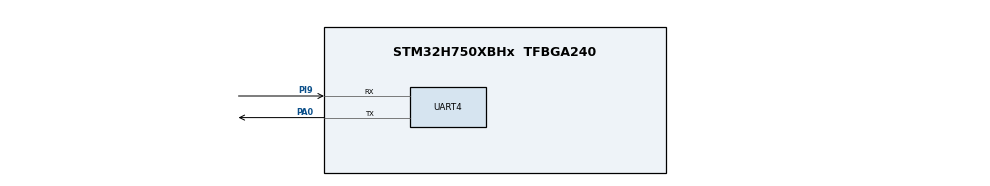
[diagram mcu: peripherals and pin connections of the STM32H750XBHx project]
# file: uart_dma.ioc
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Mcu.Family=STM32H7
Mcu.Name=STM32H750XBHx
Mcu.Package=TFBGA240
NVIC.PriorityGroup=NVIC_PRIORITYGROUP_4
NVIC.UART4_IRQn=true\:0\:0\:false\:false\:true\:true\:true\:true
PA0.Mode=Asynchronous
PA0.Signal=UART4_TX
PH0-OSC_IN\ (PH0).Mode=HSE-External-Oscillator
PH0-OSC_IN\ (PH0).PinAttribute=Free
PH0-OSC_IN\ (PH0).Signal=RCC_OSC_IN
PH1-OSC_OUT\ (PH1).Mode=HSE-External-Oscillator
PH1-OSC_OUT\ (PH1).PinAttribute=Free
PH1-OSC_OUT\ (PH1).Signal=RCC_OSC_OUT
PI9.Mode=Asynchronous
PI9.PinAttribute=Free
PI9.Signal=UART4_RX
ProjectManager.HeapSize=0x200
ProjectManager.StackSize=0x400
ProjectManager.TargetToolchain=STM32CubeIDE
RCC.ADCFreq_Value=480000000
RCC.APB1Freq_Value=120000000
RCC.APB2Freq_Value=120000000
RCC.APB3Freq_Value=120000000
RCC.APB4Freq_Value=120000000
RCC.CortexFreq_Value=480000000
RCC.D1PPRE=RCC_APB3_DIV2
RCC.D2PPRE1=RCC_APB1_DIV2
RCC.D2PPRE2=RCC_APB2_DIV2
RCC.D3PPRE=RCC_APB4_DIV2
RCC.DIVM1=5
RCC.DIVM2=5
RCC.DIVM3=5
RCC.DIVN1=192
RCC.DIVN2=192
RCC.DIVN3=192
RCC.DIVQ2=10
RCC.EnableHSEDSI-ClockTree=true
RCC.HCLKFreq_Value=240000000
RCC.HPRE=RCC_HCLK_DIV2
RCC.PLLSourceVirtual=RCC_PLLSOURCE_HSE
RCC.SYSCLKFreq_VALUE=480000000
RCC.SYSCLKSource=RCC_SYSCLKSOURCE_PLLCLK
RCC.USART234578CLockSelection=RCC_USART234578CLKSOURCE_PLL2
RCC.USBFreq_Value=480000000
board=custom

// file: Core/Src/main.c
/* USER CODE BEGIN Header */
/**
  ******************************************************************************
  * @file           : main.c
  * @brief          : Main program body
  ******************************************************************************
  * @attention
  *
  * Copyright (c) 2023 STMicroelectronics.
  * All rights reserved.
  *
  * This software is licensed under terms that can be found in the LICENSE file
  * in the root directory of this software component.
  * If no LICENSE file comes with this software, it is provided AS-IS.
  *
  ******************************************************************************
  */
/* USER CODE END Header */
#include "main.h"
#include "dma.h"
#include "usart.h"
#include "gpio.h"

/* USER CODE BEGIN Includes */
#include <string.h>
/* USER CODE END Includes */

/* USER CODE BEGIN PV */
extern volatile uint8_t uart4_rx_data;
extern volatile uint8_t uart4_rx_buff[100];
extern volatile uint8_t uart4_rx_cplt_flag;
extern volatile uint8_t uart4_tx_cplt_flag;
extern volatile uint8_t uart4_tx_buff[100];

/* USER CODE END PV */

void SystemClock_Config(void);
/* USER CODE BEGIN PFP */
#ifdef __GNUC__
//With GCC, small printf (option LD Linker->Libraries->Small printf set to 'Yes') calls __io_putchar()
#define PUTCHAR_PROTOTYPE int __io_putchar(int ch)
#else
#define PUTCHAR_PROTOTYPE int fputc(int ch, FILE *f)
#endif /* __GNUC__ */

/* USER CODE END PFP */

int main(void)
{

  /* MCU Configuration--------------------------------------------------------*/

  /* Reset of all peripherals, Initializes the Flash interface and the Systick. */
  HAL_Init();

  /* Configure the system clock */
  SystemClock_Config();

  /* Initialize all configured peripherals */
  MX_GPIO_Init();
  MX_DMA_Init();
  MX_UART4_Init();
  /* USER CODE BEGIN 2 */
  HAL_UART_Receive_IT(&huart4, &uart4_rx_data, 1);
  printf("start main\r\n");
  /* USER CODE END 2 */

  /* Infinite loop */
  /* USER CODE BEGIN WHILE */
  uint8_t print_buf[100] = {0,};
  for (int i = 0; i < 100; i++)
  {
    if(i % 10 )
      uart4_tx_buff[i] = 'z';
    else
      uart4_tx_buff[i] = '0';
  }
  uart4_tx_buff[99] = '\n';

  uint32_t pretime = HAL_GetTick();
  //HAL_UART_Transmit_DMA(&huart4, uart4_tx_buff, sizeof (uart4_tx_buff));
  uint32_t curtime = HAL_GetTick();

  while (1)
  {
    HAL_Delay(1000);
    if(uart4_rx_cplt_flag){
      pretime = HAL_GetTick();
      //printf("%s\r\n", uart4_rx_buff);
      //printf("time : %d", curtime - pretime);
      HAL_UART_Transmit_DMA(&huart4, uart4_tx_buff, sizeof (uart4_tx_buff));
      curtime = HAL_GetTick();
      //

      uart4_rx_cplt_flag = 0;
    }

    if(uart4_tx_cplt_flag){
      HAL_UART_Transmit(&huart4, uart4_tx_buff,sizeof(uart4_tx_buff),0xFFFF);
      sprintf(print_buf, "time : %d\r\n", curtime - pretime);
      HAL_UART_Transmit(&huart4, print_buf, strlen(print_buf), 0xFFFF);
      uart4_tx_cplt_flag = 0;
    }
    /* USER CODE END WHILE */

  }
}

void SystemClock_Config(void)
{
  RCC_OscInitTypeDef RCC_OscInitStruct = {0};
  RCC_ClkInitTypeDef RCC_ClkInitStruct = {0};

  /** Supply configuration update enable
  */
  HAL_PWREx_ConfigSupply(PWR_LDO_SUPPLY);

  /** Configure the main internal regulator output voltage
  */
  __HAL_PWR_VOLTAGESCALING_CONFIG(PWR_REGULATOR_VOLTAGE_SCALE0);

  while(!__HAL_PWR_GET_FLAG(PWR_FLAG_VOSRDY)) {}

  /** Macro to configure the PLL clock source
  */
  __HAL_RCC_PLL_PLLSOURCE_CONFIG(RCC_PLLSOURCE_HSE);

  /** Initializes the RCC Oscillators according to the specified parameters
  * in the RCC_OscInitTypeDef structure.
  */
  RCC_OscInitStruct.OscillatorType = RCC_OSCILLATORTYPE_HSE;
  RCC_OscInitStruct.HSEState = RCC_HSE_ON;
  RCC_OscInitStruct.PLL.PLLState = RCC_PLL_ON;
  RCC_OscInitStruct.PLL.PLLSource = RCC_PLLSOURCE_HSE;
  RCC_OscInitStruct.PLL.PLLM = 5;
  RCC_OscInitStruct.PLL.PLLN = 192;
  RCC_OscInitStruct.PLL.PLLP = 2;
  RCC_OscInitStruct.PLL.PLLQ = 2;
  RCC_OscInitStruct.PLL.PLLR = 2;
  RCC_OscInitStruct.PLL.PLLRGE = RCC_PLL1VCIRANGE_2;
  RCC_OscInitStruct.PLL.PLLVCOSEL = RCC_PLL1VCOWIDE;
  RCC_OscInitStruct.PLL.PLLFRACN = 0;
  if (HAL_RCC_OscConfig(&RCC_OscInitStruct) != HAL_OK)
  {
    Error_Handler();
  }

  /** Initializes the CPU, AHB and APB buses clocks
  */
  RCC_ClkInitStruct.ClockType = RCC_CLOCKTYPE_HCLK|RCC_CLOCKTYPE_SYSCLK
                              |RCC_CLOCKTYPE_PCLK1|RCC_CLOCKTYPE_PCLK2
                              |RCC_CLOCKTYPE_D3PCLK1|RCC_CLOCKTYPE_D1PCLK1;
  RCC_ClkInitStruct.SYSCLKSource = RCC_SYSCLKSOURCE_PLLCLK;
  RCC_ClkInitStruct.SYSCLKDivider = RCC_SYSCLK_DIV1;
  RCC_ClkInitStruct.AHBCLKDivider = RCC_HCLK_DIV2;
  RCC_ClkInitStruct.APB3CLKDivider = RCC_APB3_DIV2;
  RCC_ClkInitStruct.APB1CLKDivider = RCC_APB1_DIV2;
  RCC_ClkInitStruct.APB2CLKDivider = RCC_APB2_DIV2;
  RCC_ClkInitStruct.APB4CLKDivider = RCC_APB4_DIV2;

  if (HAL_RCC_ClockConfig(&RCC_ClkInitStruct, FLASH_LATENCY_4) != HAL_OK)
  {
    Error_Handler();
  }
}

/* USER CODE BEGIN 4 */
PUTCHAR_PROTOTYPE
{
/* Place your implementation of fputc here */
/* e.g. write a character to the USART3 and Loop until the end of transmission */
  HAL_UART_Transmit (&huart4, (uint8_t*) &ch, 1, 0xFFFF);
  return ch;
}
/* USER CODE END 4 */

void Error_Handler(void)
{
  __disable_irq();
  while (1)
  {
  }
}
